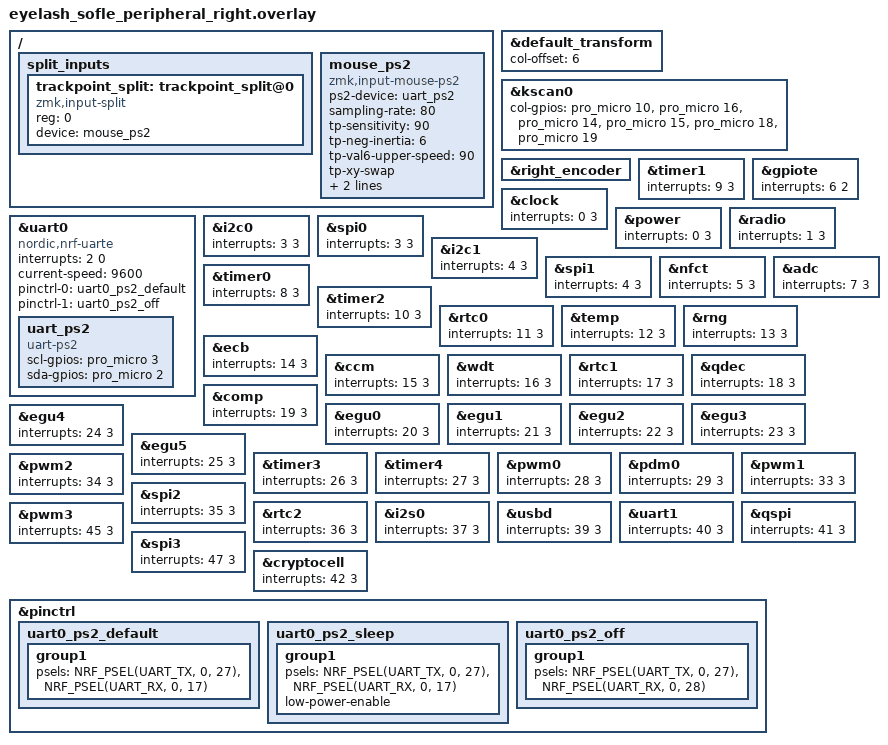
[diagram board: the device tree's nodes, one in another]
#include "eyelash_sofle.dtsi"

#include "cyn_sofle_esb_address.dtsi"

&default_transform {
    col-offset = <6>;
};

&kscan0 {
    col-gpios
        = <&pro_micro 10 GPIO_ACTIVE_HIGH>
        , <&pro_micro 16 GPIO_ACTIVE_HIGH>
        , <&pro_micro 14 GPIO_ACTIVE_HIGH>
        , <&pro_micro 15 GPIO_ACTIVE_HIGH>
        , <&pro_micro 18 GPIO_ACTIVE_HIGH>
        , <&pro_micro 19 GPIO_ACTIVE_HIGH>
        ;
};

&right_encoder {
    status = "okay";
};

&timer1 {
    status = "okay";
};

/* PS/2 Trackpoint Configuration (UART-based driver)
 * Trackpoint wired to TX/RX on XIAO BLE:
 *   D3 = P0.20 -> PS/2 Clock (SCL)
 *   D2 = P0.17 -> PS/2 Data (SDA) - UART RX
 */

/* Interrupt priority overrides for PS/2 timing */
/* GPIOTE and UART0 at priority 0 for reliable PS/2 communication */
&gpiote { interrupts = < 6 2 >; };  /* Lower priority - UART0 handles reads */
&clock { interrupts = < 0 3 >; };
&power { interrupts = < 0 3 >; };
&radio { interrupts = < 1 3 >; };
&uart0 { interrupts = < 2 0 >; };  /* Priority 0 for PS/2 UART responses */
&i2c0 { interrupts = < 3 3 >; };
&spi0 { interrupts = < 3 3 >; };
&i2c1 { interrupts = < 4 3 >; };
&spi1 { interrupts = < 4 3 >; };
&nfct { interrupts = < 5 3 >; };
&adc { interrupts = < 7 3 >; };
&timer0 { interrupts = < 8 3 >; };
&timer1 { interrupts = < 9 3 >; };
&timer2 { interrupts = < 10 3 >; };
&rtc0 { interrupts = < 11 3 >; };
&temp { interrupts = < 12 3 >; };
&rng { interrupts = < 13 3 >; };
&ecb { interrupts = < 14 3 >; };
&ccm { interrupts = < 15 3 >; };
&wdt { interrupts = < 16 3 >; };
&rtc1 { interrupts = < 17 3 >; };
&qdec { interrupts = < 18 3 >; };
&comp { interrupts = < 19 3 >; };
&egu0 { interrupts = < 20 3 >; };
&egu1 { interrupts = < 21 3 >; };
&egu2 { interrupts = < 22 3 >; };
&egu3 { interrupts = < 23 3 >; };
&egu4 { interrupts = < 24 3 >; };
&egu5 { interrupts = < 25 3 >; };
&timer3 { interrupts = < 26 3 >; };
&timer4 { interrupts = < 27 3 >; };
&pwm0 { interrupts = < 28 3 >; };
&pdm0 { interrupts = < 29 3 >; };
&pwm1 { interrupts = < 33 3 >; };
&pwm2 { interrupts = < 34 3 >; };
&spi2 { interrupts = < 35 3 >; };
&rtc2 { interrupts = < 36 3 >; };
&i2s0 { interrupts = < 37 3 >; };
&usbd { interrupts = < 39 3 >; };
&uart1 { interrupts = < 40 3 >; };
&qspi { interrupts = < 41 3 >; };
&pwm3 { interrupts = < 45 3 >; };
&spi3 { interrupts = < 47 3 >; };
&cryptocell { interrupts = < 42 3 >; };

&pinctrl {
    /* UART RX on P0.17 (D2/SDA) for PS/2 receive */
    uart0_ps2_default: uart0_ps2_default {
        group1 {
            psels = <NRF_PSEL(UART_TX, 0, 27)>,
                    <NRF_PSEL(UART_RX, 0, 17)>; /* P0.17 (Pro Micro D2 SDA) */
        };
    };

    uart0_ps2_sleep: uart0_ps2_sleep {
        group1 {
            psels = <NRF_PSEL(UART_TX, 0, 27)>,
                    <NRF_PSEL(UART_RX, 0, 17)>; /* P0.17 (Pro Micro D2 SDA) */
            low-power-enable;
        };
    };

    /* Switch UART to unexposed pins during transmit */
    uart0_ps2_off: uart0_ps2_off {
        group1 {
            psels = <NRF_PSEL(UART_TX, 0, 27)>,
                    <NRF_PSEL(UART_RX, 0, 28)>;
        };
    };
};

&uart0 {
    status = "okay";
    compatible = "nordic,nrf-uarte";
    /* current-speed = <14400>; - most usable*/
	/* current-speed = <19200>; */
	current-speed = <9600>;
    pinctrl-0 = <&uart0_ps2_default>;
    pinctrl-1 = <&uart0_ps2_off>;
    pinctrl-names = "default", "sleep";

    uart_ps2: uart_ps2 {
        status = "okay";
        compatible = "uart-ps2";
        scl-gpios = <&pro_micro 3 GPIO_ACTIVE_HIGH>; /* P0.20 (Pro Micro D3 SDA) */
        sda-gpios = <&pro_micro 2 GPIO_ACTIVE_HIGH>; /* P0.17 (Pro Micro D2 SDA) */

    };
};

/ {  
    /* Input split for forwarding trackpoint to central */
    split_inputs {
        #address-cells = <1>;
        #size-cells = <0>;

        trackpoint_split: trackpoint_split@0 {
            compatible = "zmk,input-split";
            reg = <0>;
            device = <&mouse_ps2>;
        };
    };

    /* PS/2 Trackpoint Mouse settings || Настройка чувствительности и скорости трекпоинта. */
    mouse_ps2: mouse_ps2 {
        compatible = "zmk,input-mouse-ps2";
        status = "okay";
        ps2-device = <&uart_ps2>;
		/* Reset pin on Pro Micro Pinout D4 pin (P0.22) - required for reliable init */
        /* rst-gpios = <&pro_micro 4 GPIO_ACTIVE_HIGH>; */
        sampling-rate = <80>; /* Default 80. Use 60, 80 or 100Hz(200Hz can be unstable). The frequency at which the mouse samples and sends data (in Hz). */
        tp-sensitivity = <90>; /* Default 128 How sensitive the TP is. Higher value = faster mouse movenet. Use range from 1 to 255.  */
        tp-neg-inertia = <6>; /* Default 6. Makes the TP feel more responsive and "overshoot" less. Makes cursor stop more quickly when releasing pressure. */
        tp-val6-upper-speed = <90>; /* Default 97. The maximum mouse movement speed the TP will accelarate to. */
        tp-xy-swap; 
	    tp-x-invert;
	    tp-y-invert;
    };
};
